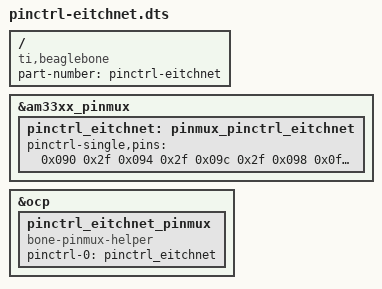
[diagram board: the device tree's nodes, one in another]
/dts-v1/;
/plugin/;

/{
  compatible = "ti,beaglebone", "ti,beaglebone-black";

  /* identification */
  part-number = "pinctrl-eitchnet";

  /* https://github.com/derekmolloy/boneDeviceTree/blob/master/docs/BeagleboneBlackP9HeaderTable.pdf */
  fragment@0 {
    target = <&am33xx_pinmux>;
    __overlay__ {
      pinctrl_eitchnet: pinmux_pinctrl_eitchnet {
        pinctrl-single,pins = <
          
          /* 0x27 INPUT  */
          0x090 0x2f /* P8_07 66 INPUT  MODE7 none */
          0x094 0x2f /* P8_08 67 INPUT  MODE7 none */
          0x09c 0x2f /* P8_09 69 INPUT  MODE7 none */

          /* 0x07 OUTPUT */          
          0x098 0x0f /* P8_10 68 OUTPUT MODE7 none */
          0x034 0x0f /* P8_11 45 OUTPUT MODE7 none */
          0x030 0x0f /* P8_12 44 OUTPUT MODE7 none */
          0x028 0x0f /* P8_14 26 OUTPUT MODE7 none */
          0x03c 0x0f /* P8_15 47 OUTPUT MODE7 none */
          0x038 0x0f /* P8_16 46 OUTPUT MODE7 none */
        >;
      };
    };
  };

  fragment@1 {
    target = <&ocp>;
    __overlay__ {
      pinctrl_eitchnet_pinmux {
        compatible = "bone-pinmux-helper";
        pinctrl-names = "default";
        pinctrl-0 = <&pinctrl_eitchnet>;
        status = "okay";
      };
    };
  };
};
